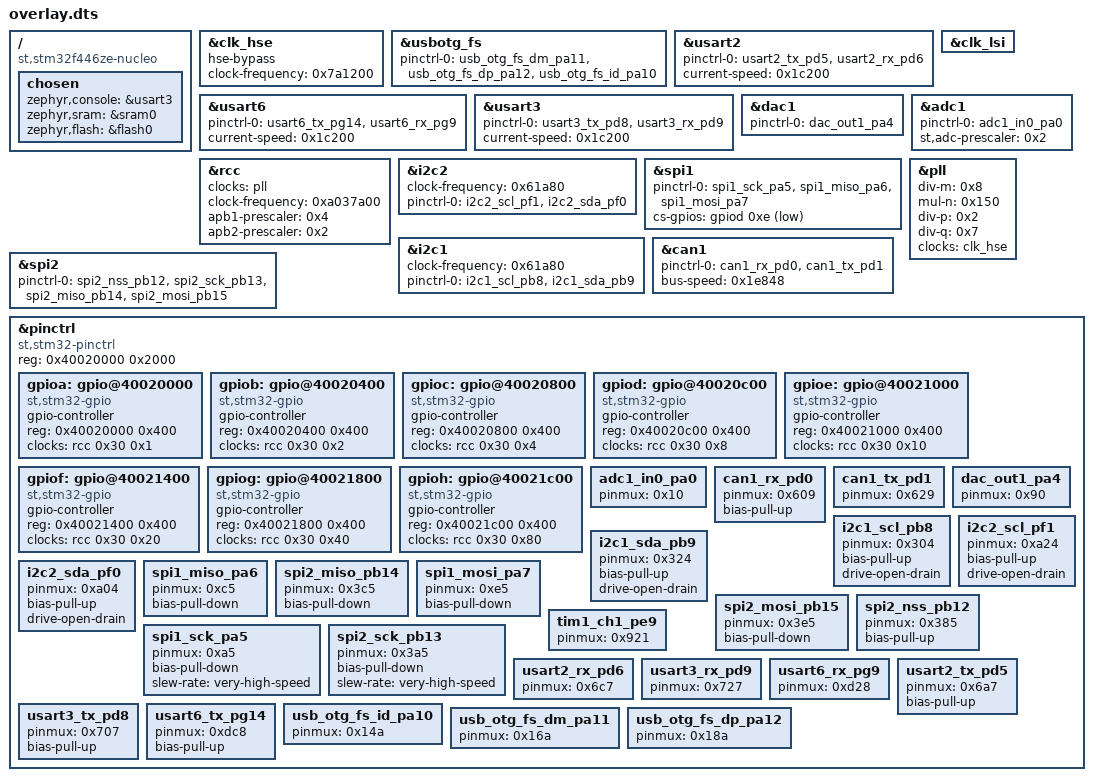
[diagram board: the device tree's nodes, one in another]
/ {
	compatible = "st,stm32f446ze-nucleo";
	chosen {
		zephyr,console = &usart3;
		zephyr,sram = &sram0;
		zephyr,flash = &flash0;
	};
};
&clk_hse{
	status = "okay";
	hse-bypass;
	clock-frequency = < 0x7a1200 >;
};
&usbotg_fs{
	status = "okay";
	pinctrl-0 = < &usb_otg_fs_dm_pa11 &usb_otg_fs_dp_pa12 &usb_otg_fs_id_pa10 >;
	pinctrl-names = "default";
};
&usart2{
	status = "okay";
	pinctrl-0 = < &usart2_tx_pd5 &usart2_rx_pd6 >;
	pinctrl-names = "default";
	current-speed = < 0x1c200 >;
};
&usart6{
	status = "okay";
	pinctrl-0 = < &usart6_tx_pg14 &usart6_rx_pg9 >;
	pinctrl-names = "default";
	current-speed = < 0x1c200 >;
};
&usart3{
	status = "okay";
	pinctrl-0 = < &usart3_tx_pd8 &usart3_rx_pd9 >;
	pinctrl-names = "default";
	current-speed = < 0x1c200 >;
};
&dac1{
	status = "okay";
	pinctrl-0 = < &dac_out1_pa4 >;
	pinctrl-names = "default";
};
&clk_lsi{
	status = "okay";
};
&adc1{
	status = "okay";
	pinctrl-0 = < &adc1_in0_pa0 >;
	pinctrl-names = "default";
	st,adc-prescaler = < 0x2 >;
};
&rcc{
	clocks = < &pll >;
	clock-frequency = < 0xa037a00 >;
	apb1-prescaler = < 0x4 >;
	apb2-prescaler = < 0x2 >;
};
&i2c2{
	clock-frequency = < 0x61a80 >;
	status = "okay";
	pinctrl-0 = < &i2c2_scl_pf1 &i2c2_sda_pf0 >;
	pinctrl-names = "default";
};
&spi1{
	status = "okay";
	pinctrl-0 = < &spi1_sck_pa5 &spi1_miso_pa6 &spi1_mosi_pa7 >;
	pinctrl-names = "default";
	cs-gpios = < &gpiod 0xe 0x11 >;
};
&pll{
	status = "okay";
	div-m = < 0x8 >;
	mul-n = < 0x150 >;
	div-p = < 0x2 >;
	div-q = < 0x7 >;
	clocks = < &clk_hse >;
};
&i2c1{
	clock-frequency = < 0x61a80 >;
	status = "okay";
	pinctrl-0 = < &i2c1_scl_pb8 &i2c1_sda_pb9 >;
	pinctrl-names = "default";
};
&spi2{
	status = "okay";
	pinctrl-0 = < &spi2_nss_pb12 &spi2_sck_pb13 &spi2_miso_pb14 &spi2_mosi_pb15 >;
	pinctrl-names = "default";
};
&can1{
	status = "okay";
	pinctrl-0 = < &can1_rx_pd0 &can1_tx_pd1 >;
	pinctrl-names = "default";
	bus-speed = < 0x1e848 >;
};
&pinctrl{
	compatible = "st,stm32-pinctrl";
	#address-cells = < 0x1 >;
	#size-cells = < 0x1 >;
	reg = < 0x40020000 0x2000 >;
	gpioa: gpio@40020000 {
		compatible = "st,stm32-gpio";
		gpio-controller;
		#gpio-cells = < 0x2 >;
		reg = < 0x40020000 0x400 >;
		clocks = < &rcc 0x30 0x1 >;
	};
	gpiob: gpio@40020400 {
		compatible = "st,stm32-gpio";
		gpio-controller;
		#gpio-cells = < 0x2 >;
		reg = < 0x40020400 0x400 >;
		clocks = < &rcc 0x30 0x2 >;
	};
	gpioc: gpio@40020800 {
		compatible = "st,stm32-gpio";
		gpio-controller;
		#gpio-cells = < 0x2 >;
		reg = < 0x40020800 0x400 >;
		clocks = < &rcc 0x30 0x4 >;
	};
	gpiod: gpio@40020c00 {
		compatible = "st,stm32-gpio";
		gpio-controller;
		#gpio-cells = < 0x2 >;
		reg = < 0x40020c00 0x400 >;
		clocks = < &rcc 0x30 0x8 >;
	};
	gpioe: gpio@40021000 {
		compatible = "st,stm32-gpio";
		gpio-controller;
		#gpio-cells = < 0x2 >;
		reg = < 0x40021000 0x400 >;
		clocks = < &rcc 0x30 0x10 >;
	};
	gpiof: gpio@40021400 {
		compatible = "st,stm32-gpio";
		gpio-controller;
		#gpio-cells = < 0x2 >;
		reg = < 0x40021400 0x400 >;
		clocks = < &rcc 0x30 0x20 >;
	};
	gpiog: gpio@40021800 {
		compatible = "st,stm32-gpio";
		gpio-controller;
		#gpio-cells = < 0x2 >;
		reg = < 0x40021800 0x400 >;
		clocks = < &rcc 0x30 0x40 >;
	};
	gpioh: gpio@40021c00 {
		compatible = "st,stm32-gpio";
		gpio-controller;
		#gpio-cells = < 0x2 >;
		reg = < 0x40021c00 0x400 >;
		clocks = < &rcc 0x30 0x80 >;
	};
	adc1_in0_pa0: adc1_in0_pa0 {
		pinmux = < 0x10 >;
	};
	can1_rx_pd0: can1_rx_pd0 {
		pinmux = < 0x609 >;
		bias-pull-up;
	};
	can1_tx_pd1: can1_tx_pd1 {
		pinmux = < 0x629 >;
	};
	dac_out1_pa4: dac_out1_pa4 {
		pinmux = < 0x90 >;
	};
	i2c1_scl_pb8: i2c1_scl_pb8 {
		pinmux = < 0x304 >;
		bias-pull-up;
		drive-open-drain;
	};
	i2c2_scl_pf1: i2c2_scl_pf1 {
		pinmux = < 0xa24 >;
		bias-pull-up;
		drive-open-drain;
	};
	i2c1_sda_pb9: i2c1_sda_pb9 {
		pinmux = < 0x324 >;
		bias-pull-up;
		drive-open-drain;
	};
	i2c2_sda_pf0: i2c2_sda_pf0 {
		pinmux = < 0xa04 >;
		bias-pull-up;
		drive-open-drain;
	};
	spi1_miso_pa6: spi1_miso_pa6 {
		pinmux = < 0xc5 >;
		bias-pull-down;
	};
	spi2_miso_pb14: spi2_miso_pb14 {
		pinmux = < 0x3c5 >;
		bias-pull-down;
	};
	spi1_mosi_pa7: spi1_mosi_pa7 {
		pinmux = < 0xe5 >;
		bias-pull-down;
	};
	spi2_mosi_pb15: spi2_mosi_pb15 {
		pinmux = < 0x3e5 >;
		bias-pull-down;
	};
	spi2_nss_pb12: spi2_nss_pb12 {
		pinmux = < 0x385 >;
		bias-pull-up;
	};
	spi1_sck_pa5: spi1_sck_pa5 {
		pinmux = < 0xa5 >;
		bias-pull-down;
		slew-rate = "very-high-speed";
	};
	spi2_sck_pb13: spi2_sck_pb13 {
		pinmux = < 0x3a5 >;
		bias-pull-down;
		slew-rate = "very-high-speed";
	};
	tim1_ch1_pe9: tim1_ch1_pe9 {
		pinmux = < 0x921 >;
	};
	usart2_rx_pd6: usart2_rx_pd6 {
		pinmux = < 0x6c7 >;
	};
	usart3_rx_pd9: usart3_rx_pd9 {
		pinmux = < 0x727 >;
	};
	usart6_rx_pg9: usart6_rx_pg9 {
		pinmux = < 0xd28 >;
	};
	usart2_tx_pd5: usart2_tx_pd5 {
		pinmux = < 0x6a7 >;
		bias-pull-up;
	};
	usart3_tx_pd8: usart3_tx_pd8 {
		pinmux = < 0x707 >;
		bias-pull-up;
	};
	usart6_tx_pg14: usart6_tx_pg14 {
		pinmux = < 0xdc8 >;
		bias-pull-up;
	};
	usb_otg_fs_id_pa10: usb_otg_fs_id_pa10 {
		pinmux = < 0x14a >;
	};
	usb_otg_fs_dm_pa11: usb_otg_fs_dm_pa11 {
		pinmux = < 0x16a >;
	};
	usb_otg_fs_dp_pa12: usb_otg_fs_dp_pa12 {
		pinmux = < 0x18a >;
	};
};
